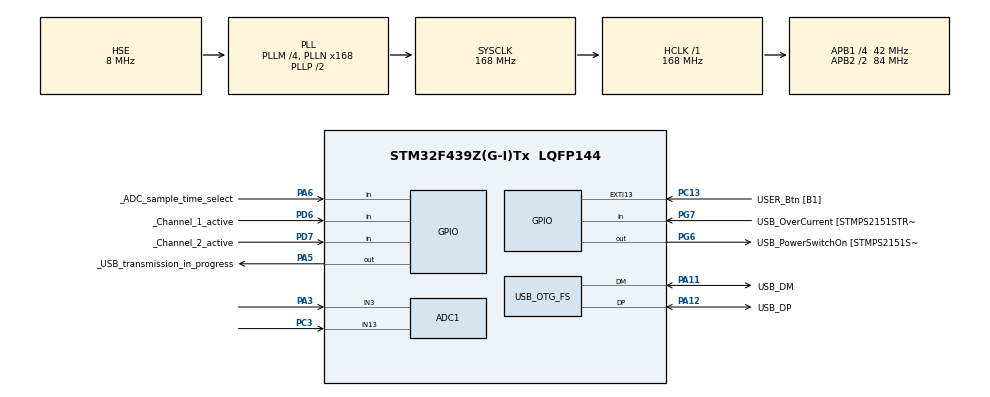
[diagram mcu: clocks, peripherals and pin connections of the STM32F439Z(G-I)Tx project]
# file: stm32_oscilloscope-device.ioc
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ADC1.Channel-0\#ChannelRegularConversion=ADC_CHANNEL_3
ADC1.Channel-1\#ChannelRegularConversion=ADC_CHANNEL_13
ADC1.ContinuousConvMode=ENABLE
ADC1.DMAContinuousRequests=ENABLE
ADC1.EOCSelection=ADC_EOC_SEQ_CONV
ADC1.ExternalTrigConv=ADC_SOFTWARE_START
ADC1.Mode=ADC_TRIPLEMODE_INTERL
ADC1.NbrOfConversion=2
ADC1.NbrOfConversionFlag=1
ADC1.Rank-0\#ChannelRegularConversion=1
ADC1.Rank-1\#ChannelRegularConversion=2
ADC1.SamplingTime-0\#ChannelRegularConversion=ADC_SAMPLETIME_3CYCLES
ADC1.SamplingTime-1\#ChannelRegularConversion=ADC_SAMPLETIME_3CYCLES
ADC1.ScanConvMode=ENABLE
ADC1.master=1
ADC2.Channel-0\#ChannelRegularConversion=ADC_CHANNEL_3
ADC2.Channel-1\#ChannelRegularConversion=ADC_CHANNEL_13
ADC2.DMAAccessMode=ADC_DMAACCESSMODE_2
ADC2.EOCSelection=ADC_EOC_SEQ_CONV
ADC2.Mode=ADC_TRIPLEMODE_INTERL
ADC2.NbrOfConversion=2
ADC2.NbrOfConversionFlag=1
ADC2.Rank-0\#ChannelRegularConversion=1
ADC2.Rank-1\#ChannelRegularConversion=2
ADC2.SamplingTime-0\#ChannelRegularConversion=ADC_SAMPLETIME_3CYCLES
ADC2.SamplingTime-1\#ChannelRegularConversion=ADC_SAMPLETIME_3CYCLES
ADC2.ScanConvMode=ENABLE
ADC3.Channel-0\#ChannelRegularConversion=ADC_CHANNEL_3
ADC3.Channel-1\#ChannelRegularConversion=ADC_CHANNEL_13
ADC3.EOCSelection=ADC_EOC_SEQ_CONV
ADC3.NbrOfConversion=2
ADC3.NbrOfConversionFlag=1
ADC3.Rank-0\#ChannelRegularConversion=1
ADC3.Rank-1\#ChannelRegularConversion=2
ADC3.SamplingTime-0\#ChannelRegularConversion=ADC_SAMPLETIME_3CYCLES
ADC3.SamplingTime-1\#ChannelRegularConversion=ADC_SAMPLETIME_3CYCLES
ADC3.ScanConvMode=ENABLE
Dma.ADC1.0.Direction=DMA_PERIPH_TO_MEMORY
Dma.ADC1.0.FIFOMode=DMA_FIFOMODE_DISABLE
Dma.ADC1.0.Instance=DMA2_Stream0
Dma.ADC1.0.MemDataAlignment=DMA_MDATAALIGN_WORD
Dma.ADC1.0.MemInc=DMA_MINC_ENABLE
Dma.ADC1.0.Mode=DMA_NORMAL
Dma.ADC1.0.PeriphDataAlignment=DMA_PDATAALIGN_WORD
Dma.ADC1.0.PeriphInc=DMA_PINC_DISABLE
Dma.ADC1.0.Priority=DMA_PRIORITY_VERY_HIGH
Dma.Request0=ADC1
Mcu.Family=STM32F4
Mcu.Name=STM32F439Z(G-I)Tx
Mcu.Package=LQFP144
NVIC.ADC_IRQn=true\:0\:0\:false\:false\:true\:true\:true\:true
NVIC.DMA2_Stream0_IRQn=true\:0\:0\:false\:false\:true\:false\:true\:true
NVIC.OTG_FS_IRQn=true\:0\:0\:false\:false\:true\:false\:true\:true
NVIC.PriorityGroup=NVIC_PRIORITYGROUP_4
PA10.GPIO_Label=USB_ID
PA10.Signal=USB_OTG_FS_ID
PA11.GPIO_Label=USB_DM
PA11.Mode=Device_Only
PA11.Signal=USB_OTG_FS_DM
PA12.GPIO_Label=USB_DP
PA12.Mode=Device_Only
PA12.Signal=USB_OTG_FS_DP
PA13.GPIO_Label=TMS
PA13.Mode=Serial_Wire
PA13.Signal=SYS_JTMS-SWDIO
PA14.GPIO_Label=TCK
PA14.Mode=Serial_Wire
PA14.Signal=SYS_JTCK-SWCLK
PA3.Signal=ADCx_IN3
PA5.GPIO_Label=_USB_transmission_in_progress
PA5.Signal=GPIO_Output
PA6.GPIO_Label=_ADC_sample_time_select
PA6.GPIO_PuPd=GPIO_PULLUP
PA6.Signal=GPIO_Input
PA8.GPIO_Label=USB_SOF [TP1]
PA8.Signal=USB_OTG_FS_SOF
PA9.GPIO_Label=USB_VBUS
PA9.Signal=USB_OTG_FS_VBUS
PC13.GPIO_Label=USER_Btn [B1]
PC13.Signal=GPXTI13
PC14/OSC32_IN.Mode=LSE-External-Oscillator
PC14/OSC32_IN.Signal=RCC_OSC32_IN
PC15/OSC32_OUT.Mode=LSE-External-Oscillator
PC15/OSC32_OUT.Signal=RCC_OSC32_OUT
PC3.Signal=ADCx_IN13
PD6.GPIO_Label=_Channel_1_active
PD6.GPIO_PuPd=GPIO_PULLUP
PD6.Signal=GPIO_Input
PD7.GPIO_Label=_Channel_2_active
PD7.GPIO_PuPd=GPIO_PULLUP
PD7.Signal=GPIO_Input
PG6.GPIO_Label=USB_PowerSwitchOn [STMPS2151STR_EN]
PG6.Signal=GPIO_Output
PG7.GPIO_Label=USB_OverCurrent [STMPS2151STR_FAULT]
PG7.Signal=GPIO_Input
PH0/OSC_IN.GPIO_Label=MCO [STM32F103CBT6_PA8]
PH0/OSC_IN.Mode=HSE-External-Clock-Source
PH0/OSC_IN.Signal=RCC_OSC_IN
PH1/OSC_OUT.Mode=HSE-External-Clock-Source
PH1/OSC_OUT.Signal=RCC_OSC_OUT
ProjectManager.HeapSize=0x200
ProjectManager.StackSize=0x400
ProjectManager.TargetToolchain=Makefile
RCC.48MHZClocksFreq_Value=48000000
RCC.AHBFreq_Value=168000000
RCC.APB1CLKDivider=RCC_HCLK_DIV4
RCC.APB1Freq_Value=42000000
RCC.APB1TimFreq_Value=84000000
RCC.APB2CLKDivider=RCC_HCLK_DIV2
RCC.APB2Freq_Value=84000000
RCC.APB2TimCLKDivider=2
RCC.APB2TimFreq_Value=168000000
RCC.CortexFreq_Value=168000000
RCC.HCLKFreq_Value=168000000
RCC.HSE_VALUE=8000000
RCC.HSI_VALUE=16000000
RCC.PLLM=4
RCC.PLLMUL=RCC_PLL_MUL9
RCC.PLLN=168
RCC.PLLQ=7
RCC.PRESCALERUSB=RCC_USBCLKSOURCE_PLL_DIV1_5
RCC.SYSCLKFreq_VALUE=168000000
RCC.SYSCLKSource=RCC_SYSCLKSOURCE_PLLCLK
RCC.SYSCLKSourceVirtual=RCC_SYSCLKSOURCE_PLLCLK
RCC.USBFreq_Value=48000000
RCC.VCOOutputFreq_Value=336000000
SH.ADCx_IN13.0=ADC1_IN13,IN13
SH.ADCx_IN13.1=ADC2_IN13,IN13
SH.ADCx_IN13.2=ADC3_IN13,IN13
SH.ADCx_IN3.0=ADC1_IN3,IN3
SH.ADCx_IN3.1=ADC2_IN3,IN3
SH.ADCx_IN3.2=ADC3_IN3,IN3
USB_DEVICE.CLASS_NAME_FS=CDC
USB_DEVICE.VirtualMode-CDC_FS=Cdc
USB_DEVICE.VirtualModeFS=Cdc_FS
USB_OTG_FS.Sof_enable=DISABLE
USB_OTG_FS.VirtualMode=Device_Only
VP_TIM2_VS_ClockSourceINT.Mode=Internal
VP_USB_DEVICE_VS_USB_DEVICE_CDC_FS.Mode=CDC_FS
board=NUCLEO-F439ZI

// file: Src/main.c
/* USER CODE BEGIN Header */
/**
 ******************************************************************************
 * @file           : main.c
 * @brief          : Main program body
 ******************************************************************************
 * @attention
 *
 * Copyright (c) 2024 STMicroelectronics.
 * All rights reserved.
 *
 * This software is licensed under terms that can be found in the LICENSE file
 * in the root directory of this software component.
 * If no LICENSE file comes with this software, it is provided AS-IS.
 *
 ******************************************************************************
 */
/* USER CODE END Header */
#include "main.h"
#include "adc.h"
#include "dma.h"
#include "tim.h"
#include "usb_device.h"
#include "gpio.h"

/* USER CODE BEGIN Includes */
#include "oscilloscope_logic/oscilloscope_logic.h"
/* USER CODE END Includes */

void SystemClock_Config(void);

int main(void)
{

  /* MCU Configuration--------------------------------------------------------*/

  /* Reset of all peripherals, Initializes the Flash interface and the Systick. */
  HAL_Init();

  /* Configure the system clock */
  SystemClock_Config();

  /* Initialize all configured peripherals */
  MX_GPIO_Init();
  MX_DMA_Init();
  MX_USB_DEVICE_Init();
  MX_ADC1_Init();
  MX_TIM2_Init();
  MX_ADC2_Init();
  MX_ADC3_Init();
  /* USER CODE BEGIN 2 */

    oscilloscope_init();

  /* USER CODE END 2 */

  /* Infinite loop */
  /* USER CODE BEGIN WHILE */
    while (1)
    {
       oscilloscope_single_iteration();
    /* USER CODE END WHILE */

    }
}

void SystemClock_Config(void)
{
  RCC_OscInitTypeDef RCC_OscInitStruct = {0};
  RCC_ClkInitTypeDef RCC_ClkInitStruct = {0};

  /** Configure the main internal regulator output voltage
  */
  __HAL_RCC_PWR_CLK_ENABLE();
  __HAL_PWR_VOLTAGESCALING_CONFIG(PWR_REGULATOR_VOLTAGE_SCALE1);

  /** Initializes the RCC Oscillators according to the specified parameters
  * in the RCC_OscInitTypeDef structure.
  */
  RCC_OscInitStruct.OscillatorType = RCC_OSCILLATORTYPE_HSE;
  RCC_OscInitStruct.HSEState = RCC_HSE_BYPASS;
  RCC_OscInitStruct.PLL.PLLState = RCC_PLL_ON;
  RCC_OscInitStruct.PLL.PLLSource = RCC_PLLSOURCE_HSE;
  RCC_OscInitStruct.PLL.PLLM = 4;
  RCC_OscInitStruct.PLL.PLLN = 168;
  RCC_OscInitStruct.PLL.PLLP = RCC_PLLP_DIV2;
  RCC_OscInitStruct.PLL.PLLQ = 7;
  if (HAL_RCC_OscConfig(&RCC_OscInitStruct) != HAL_OK)
  {
    Error_Handler();
  }

  /** Initializes the CPU, AHB and APB buses clocks
  */
  RCC_ClkInitStruct.ClockType = RCC_CLOCKTYPE_HCLK|RCC_CLOCKTYPE_SYSCLK
                              |RCC_CLOCKTYPE_PCLK1|RCC_CLOCKTYPE_PCLK2;
  RCC_ClkInitStruct.SYSCLKSource = RCC_SYSCLKSOURCE_PLLCLK;
  RCC_ClkInitStruct.AHBCLKDivider = RCC_SYSCLK_DIV1;
  RCC_ClkInitStruct.APB1CLKDivider = RCC_HCLK_DIV4;
  RCC_ClkInitStruct.APB2CLKDivider = RCC_HCLK_DIV2;

  if (HAL_RCC_ClockConfig(&RCC_ClkInitStruct, FLASH_LATENCY_5) != HAL_OK)
  {
    Error_Handler();
  }
}

void Error_Handler(void)
{
    __disable_irq();
    while (1)
    {
    }
}

#ifdef  USE_FULL_ASSERT
/**
  * @brief  Reports the name of the source file and the source line number
  *         where the assert_param error has occurred.
  * @param  file: pointer to the source file name
  * @param  line: assert_param error line source number
  * @retval None
  */
void assert_failed(uint8_t *file, uint32_t line)
{
  /* USER CODE BEGIN 6 */
    /* User can add his own implementation to report the file name and line
       number, ex: printf("Wrong parameters value: file %s on line %d\r\n", file,
       line) */
  /* USER CODE END 6 */
}
#endif /* USE_FULL_ASSERT */
